# GMAC1 register map
Registers from a debugger description file.
Registers are 32-bit, access not given, no defined reset value unless marked. A register's access mark holds for its fields unless they carry their own. Addresses are absolute; registers are grouped by the start of their names; lines under a group give offsets from that group; [hi:lo] are bit positions; {n}, {i} and the like mark numbered series; 'fields as' and 'values as' point back to an identical list; <NAME> marks a mode.

## GMAC1
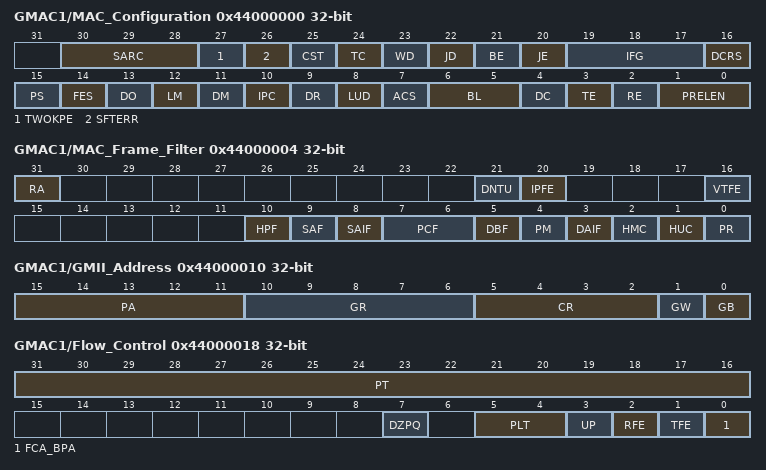
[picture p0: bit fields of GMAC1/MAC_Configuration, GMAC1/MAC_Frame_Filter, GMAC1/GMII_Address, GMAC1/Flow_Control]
0x44000000 GMAC1/MAC_Configuration
  [30:28] SARC, [27] TWOKPE, [26] SFTERR, [25] CST, [24] TC, [23] WD, [22] JD, [21] BE, [20] JE, [19:17] IFG, [16] DCRS, [15] PS, [14] FES, [13] DO, [12] LM, [11] DM, [10] IPC, [9] DR, [8] LUD, [7] ACS, [6:5] BL, [4] DC, [3] TE, [2] RE, [1:0] PRELEN
0x44000004 GMAC1/MAC_Frame_Filter
  [31] RA, [21] DNTU, [20] IPFE, [16] VTFE, [10] HPF, [9] SAF, [8] SAIF, [7:6] PCF, [5] DBF, [4] PM, [3] DAIF, [2] HMC, [1] HUC, [0] PR
0x44000010 GMAC1/GMII_Address
  [15:11] PA, [10:6] GR, [5:2] CR, [1] GW, [0] GB
0x44000014 GMAC1/GMII_Data
  [15:0] GD
0x44000018 GMAC1/Flow_Control
  [31:16] PT, [7] DZPQ, [5:4] PLT, [3] UP, [2] RFE, [1] TFE, [0] FCA_BPA
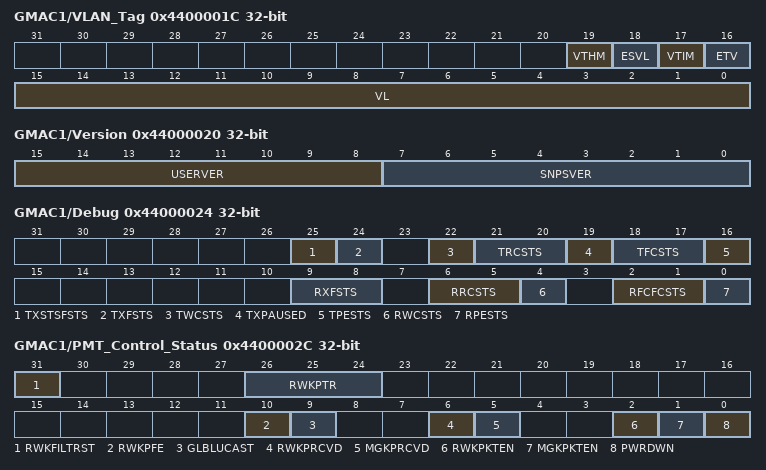
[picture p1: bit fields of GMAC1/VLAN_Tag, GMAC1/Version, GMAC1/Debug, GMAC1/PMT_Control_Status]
0x4400001C GMAC1/VLAN_Tag
  [19] VTHM, [18] ESVL, [17] VTIM, [16] ETV, [15:0] VL
0x44000020 GMAC1/Version ro
  [15:8] USERVER, [7:0] SNPSVER
0x44000024 GMAC1/Debug ro
  [25] TXSTSFSTS, [24] TXFSTS, [22] TWCSTS, [21:20] TRCSTS, [19] TXPAUSED, [18:17] TFCSTS, [16] TPESTS, [9:8] RXFSTS, [6:5] RRCSTS, [4] RWCSTS, [2:1] RFCFCSTS, [0] RPESTS
0x44000028 GMAC1/Remote_Wake_Up_Frame_Filter
  [31:0] WKUPFRMFTR
0x4400002C GMAC1/PMT_Control_Status
  [31] RWKFILTRST, [26:24] RWKPTR, [10] RWKPFE, [9] GLBLUCAST, [6] RWKPRCVD, [5] MGKPRCVD, [2] RWKPKTEN, [1] MGKPKTEN, [0] PWRDWN
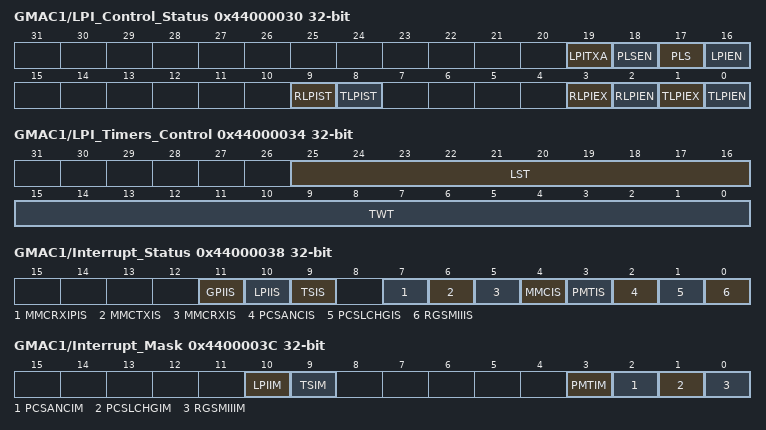
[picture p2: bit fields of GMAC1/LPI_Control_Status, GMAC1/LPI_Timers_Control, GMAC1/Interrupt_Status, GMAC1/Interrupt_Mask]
0x44000030 GMAC1/LPI_Control_Status
  [19] LPITXA, [18] PLSEN, [17] PLS, [16] LPIEN, [9] RLPIST, [8] TLPIST, [3] RLPIEX, [2] RLPIEN, [1] TLPIEX, [0] TLPIEN
0x44000034 GMAC1/LPI_Timers_Control
  [25:16] LST, [15:0] TWT
0x44000038 GMAC1/Interrupt_Status ro
  [11] GPIIS, [10] LPIIS, [9] TSIS, [7] MMCRXIPIS, [6] MMCTXIS, [5] MMCRXIS, [4] MMCIS, [3] PMTIS, [2] PCSANCIS, [1] PCSLCHGIS, [0] RGSMIIIS
0x4400003C GMAC1/Interrupt_Mask
  [10] LPIIM, [9] TSIM, [3] PMTIM, [2] PCSANCIM, [1] PCSLCHGIM, [0] RGSMIIIM
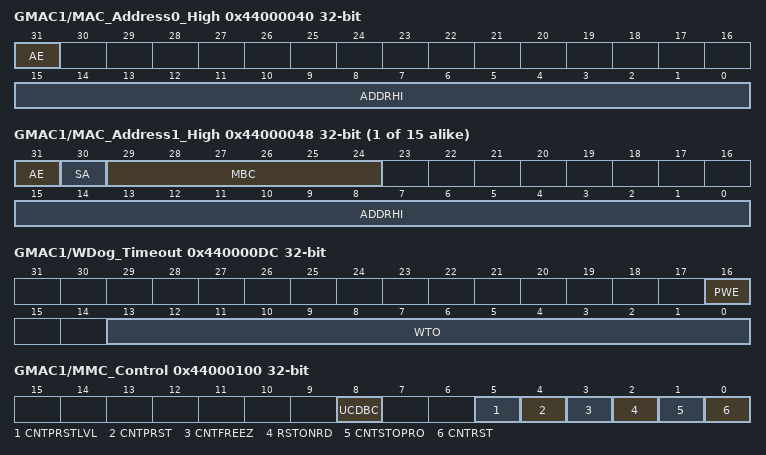
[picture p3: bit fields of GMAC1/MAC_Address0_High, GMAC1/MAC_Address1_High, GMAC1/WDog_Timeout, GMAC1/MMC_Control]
0x44000040 GMAC1/MAC_Address0_High
  [31] AE, [15:0] ADDRHI
{0x44000044+8i} GMAC1/MAC_Address{i}_Low (i=0..15)
  [31:0] ADDRLO
{0x44000040+8i} GMAC1/MAC_Address{i}_High (i=1..15)
  [31] AE, [30] SA, [29:24] MBC, [15:0] ADDRHI
0x440000DC GMAC1/WDog_Timeout
  [16] PWE, [13:0] WTO
0x44000100 GMAC1/MMC_Control
  [8] UCDBC, [5] CNTPRSTLVL, [4] CNTPRST, [3] CNTFREEZ, [2] RSTONRD, [1] CNTSTOPRO, [0] CNTRST
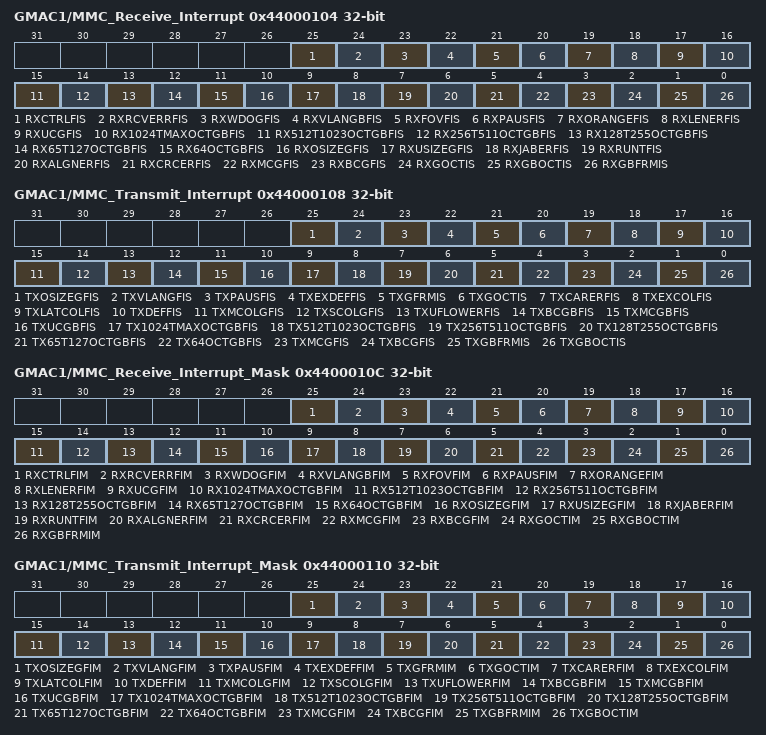
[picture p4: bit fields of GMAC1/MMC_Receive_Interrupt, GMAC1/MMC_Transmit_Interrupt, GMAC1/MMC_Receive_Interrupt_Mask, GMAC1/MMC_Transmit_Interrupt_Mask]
0x44000104 GMAC1/MMC_Receive_Interrupt ro
  [25] RXCTRLFIS, [24] RXRCVERRFIS, [23] RXWDOGFIS, [22] RXVLANGBFIS, [21] RXFOVFIS, [20] RXPAUSFIS, [19] RXORANGEFIS, [18] RXLENERFIS, [17] RXUCGFIS, [16] RX1024TMAXOCTGBFIS, [15] RX512T1023OCTGBFIS, [14] RX256T511OCTGBFIS, [13] RX128T255OCTGBFIS, [12] RX65T127OCTGBFIS, [11] RX64OCTGBFIS, [10] RXOSIZEGFIS, [9] RXUSIZEGFIS, [8] RXJABERFIS, [7] RXRUNTFIS, [6] RXALGNERFIS, [5] RXCRCERFIS, [4] RXMCGFIS, [3] RXBCGFIS, [2] RXGOCTIS, [1] RXGBOCTIS, [0] RXGBFRMIS
0x44000108 GMAC1/MMC_Transmit_Interrupt ro
  [25] TXOSIZEGFIS, [24] TXVLANGFIS, [23] TXPAUSFIS, [22] TXEXDEFFIS, [21] TXGFRMIS, [20] TXGOCTIS, [19] TXCARERFIS, [18] TXEXCOLFIS, [17] TXLATCOLFIS, [16] TXDEFFIS, [15] TXMCOLGFIS, [14] TXSCOLGFIS, [13] TXUFLOWERFIS, [12] TXBCGBFIS, [11] TXMCGBFIS, [10] TXUCGBFIS, [9] TX1024TMAXOCTGBFIS, [8] TX512T1023OCTGBFIS, [7] TX256T511OCTGBFIS, [6] TX128T255OCTGBFIS, [5] TX65T127OCTGBFIS, [4] TX64OCTGBFIS, [3] TXMCGFIS, [2] TXBCGFIS, [1] TXGBFRMIS, [0] TXGBOCTIS
0x4400010C GMAC1/MMC_Receive_Interrupt_Mask
  [25] RXCTRLFIM, [24] RXRCVERRFIM, [23] RXWDOGFIM, [22] RXVLANGBFIM, [21] RXFOVFIM, [20] RXPAUSFIM, [19] RXORANGEFIM, [18] RXLENERFIM, [17] RXUCGFIM, [16] RX1024TMAXOCTGBFIM, [15] RX512T1023OCTGBFIM, [14] RX256T511OCTGBFIM, [13] RX128T255OCTGBFIM, [12] RX65T127OCTGBFIM, [11] RX64OCTGBFIM, [10] RXOSIZEGFIM, [9] RXUSIZEGFIM, [8] RXJABERFIM, [7] RXRUNTFIM, [6] RXALGNERFIM, [5] RXCRCERFIM, [4] RXMCGFIM, [3] RXBCGFIM, [2] RXGOCTIM, [1] RXGBOCTIM, [0] RXGBFRMIM
0x44000110 GMAC1/MMC_Transmit_Interrupt_Mask
  [25] TXOSIZEGFIM, [24] TXVLANGFIM, [23] TXPAUSFIM, [22] TXEXDEFFIM, [21] TXGFRMIM, [20] TXGOCTIM, [19] TXCARERFIM, [18] TXEXCOLFIM, [17] TXLATCOLFIM, [16] TXDEFFIM, [15] TXMCOLGFIM, [14] TXSCOLGFIM, [13] TXUFLOWERFIM, [12] TXBCGBFIM, [11] TXMCGBFIM, [10] TXUCGBFIM, [9] TX1024TMAXOCTGBFIM, [8] TX512T1023OCTGBFIM, [7] TX256T511OCTGBFIM, [6] TX128T255OCTGBFIM, [5] TX65T127OCTGBFIM, [4] TX64OCTGBFIM, [3] TXMCGFIM, [2] TXBCGFIM, [1] TXGBFRMIM, [0] TXGBOCTIM
0x44000114 GMAC1/Tx_Octet_Count_Good_Bad ro
  [31:0] TXOCTGB
0x44000118 GMAC1/Tx_Frame_Count_Good_Bad ro
  [31:0] TXFRMGB
0x4400011C GMAC1/Tx_Broadcast_Frames_Good ro
  [31:0] TXBCASTG
0x44000120 GMAC1/Tx_Multicast_Frames_Good ro
  [31:0] TXMCASTG
0x44000124 GMAC1/Tx_64Octets_Frames_Good_Bad ro
  [31:0] TX64OCTGB
0x44000128 GMAC1/Tx_65To127Octets_Frames_Good_Bad ro
  [31:0] TX65_127OCTGB
0x4400012C GMAC1/Tx_128To255Octets_Frames_Good_Bad ro
  [31:0] TX128_255OCTGB
0x44000130 GMAC1/Tx_256To511Octets_Frames_Good_Bad ro
  [31:0] TX256_511OCTGB
0x44000134 GMAC1/Tx_512To1023Octets_Frames_Good_Bad ro
  [31:0] TX512_1023OCTGB
0x44000138 GMAC1/Tx_1024ToMaxOctets_Frames_Good_Bad ro
  [31:0] TX1024_MAXOCTGB
0x4400013C GMAC1/Tx_Unicast_Frames_Good_Bad ro
  [31:0] TXUCASTGB
0x44000140 GMAC1/Tx_Multicast_Frames_Good_Bad ro
  [31:0] TXMCASTGB
0x44000144 GMAC1/Tx_Broadcast_Frames_Good_Bad ro
  [31:0] TXBCASTGB
0x44000148 GMAC1/Tx_Underflow_Error_Frames ro
  [15:0] TXUNDRFLW
0x4400014C GMAC1/Tx_Single_Collision_Good_Frames ro
  [15:0] TXSNGLCOLG
0x44000150 GMAC1/Tx_Multiple_Collision_Good_Frames ro
  [15:0] TXMULTCOLG
0x44000154 GMAC1/Tx_Deferred_Frames ro
  [15:0] TXDEFRD
0x44000158 GMAC1/Tx_Late_Collision_Frames ro
  [15:0] TXLATECOL
0x4400015C GMAC1/Tx_Excessive_Collision_Frames ro
  [15:0] TXEXSCOL
0x44000160 GMAC1/Tx_Carrier_Error_Frames ro
  [15:0] TXCARR
0x44000164 GMAC1/Tx_Octet_Count_Good ro
  [31:0] TXOCTG
0x44000168 GMAC1/Tx_Frame_Count_Good ro
  [31:0] TXFRMG
0x4400016C GMAC1/Tx_Excessive_Deferral_Error ro
  [15:0] TXEXSDEF
0x44000170 GMAC1/Tx_Pause_Frames ro
  [15:0] TXPAUSE
0x44000174 GMAC1/Tx_VLAN_Frames_Good ro
  [31:0] TXVLANG
0x44000178 GMAC1/Tx_OSize_Frames_Good ro
  [15:0] TXOSIZG
0x44000180 GMAC1/Rx_Frames_Count_Good_Bad ro
  [31:0] RXFRMGB
0x44000184 GMAC1/Rx_Octet_Count_Good_Bad ro
  [31:0] RXOCTGB
0x44000188 GMAC1/Rx_Octet_Count_Good ro
  [31:0] RXOCTG
0x4400018C GMAC1/Rx_Broadcast_Frames_Good ro
  [31:0] RXBCASTG
0x44000190 GMAC1/Rx_Multicast_Frames_Good ro
  [31:0] RXMCASTG
0x44000194 GMAC1/Rx_CRC_Error_Frames ro
  [15:0] RXCRCERR
0x44000198 GMAC1/Rx_Alignment_Error_Frames ro
  [15:0] RXALGNERR
0x4400019C GMAC1/Rx_Runt_Error_Frames ro
  [15:0] RXRUNTERR
0x440001A0 GMAC1/Rx_Jabber_Error_Frames ro
  [15:0] RXJABERR
0x440001A4 GMAC1/Rx_Undersize_Frames_Good ro
  [15:0] RXUNDERSZG
0x440001A8 GMAC1/Rx_Oversize_Frames_Good ro
  [15:0] RXOVERSZG
0x440001AC GMAC1/Rx_64Octets_Frames_Good_Bad ro
  [31:0] RX64OCTGB
0x440001B0 GMAC1/Rx_65To127Octets_Frames_Good_Bad ro
  [31:0] RX65_127OCTGB
0x440001B4 GMAC1/Rx_128To255Octets_Frames_Good_Bad ro
  [31:0] RX128_255OCTGB
0x440001B8 GMAC1/Rx_256To511Octets_Frames_Good_Bad ro
  [31:0] RX256_511OCTGB
0x440001BC GMAC1/Rx_512To1023Octets_Frames_Good_Bad ro
  [31:0] RX512_1023OCTGB
0x440001C0 GMAC1/Rx_1024ToMaxOctets_Frames_Good_Bad ro
  [31:0] RX1024_MAXOCTGB
0x440001C4 GMAC1/Rx_Unicast_Frames_Good ro
  [31:0] RXUCASTG
0x440001C8 GMAC1/Rx_Length_Error_Frames ro
  [15:0] RXLENERR
0x440001CC GMAC1/Rx_Out_Of_Range_Type_Frames ro
  [15:0] RXOUTOFRNG
0x440001D0 GMAC1/Rx_Pause_Frames ro
  [15:0] RXPAUSEFRM
0x440001D4 GMAC1/Rx_FIFO_Overflow_Frames ro
  [15:0] RXFIFOOVFL
0x440001D8 GMAC1/Rx_VLAN_Frames_Good_Bad ro
  [31:0] RXVLANFRGB
0x440001DC GMAC1/Rx_Watchdog_Error_Frames ro
  [15:0] RXWDGERR
0x440001E0 GMAC1/Rx_Receive_Error_Frames ro
  [15:0] RXRCVERR
0x440001E4 GMAC1/Rx_Control_Frames_Good ro
  [31:0] RXCTRLG
{0x44000500+4i} GMAC1/Hash_Table_Reg{i} (i=0..5)
  [31:0] HT{32i+31}T{32i}
0x44000518 GMAC1/Hash_Table_Reg6
  [31:0] HT223T196
0x4400051C GMAC1/Hash_Table_Reg7
  [31:0] HT255T224
0x44000588 GMAC1/VLAN_Hash_Table_Reg
  [15:0] VLHT
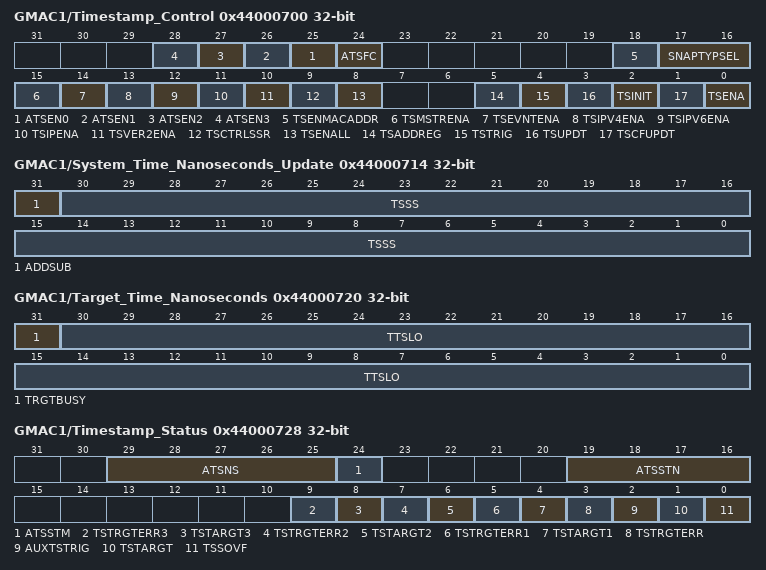
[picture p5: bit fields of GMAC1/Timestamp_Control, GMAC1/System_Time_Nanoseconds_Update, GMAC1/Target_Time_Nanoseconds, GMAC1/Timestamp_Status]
0x44000700 GMAC1/Timestamp_Control
  [n+25] ATSEN{n} (n=0..3), [24] ATSFC, [18] TSENMACADDR, [17:16] SNAPTYPSEL, [15] TSMSTRENA, [14] TSEVNTENA, [13] TSIPV4ENA, [12] TSIPV6ENA, [11] TSIPENA, [10] TSVER2ENA, [9] TSCTRLSSR, [8] TSENALL, [5] TSADDREG, [4] TSTRIG, [3] TSUPDT, [2] TSINIT, [1] TSCFUPDT, [0] TSENA
0x44000704 GMAC1/Sub_Second_Increment
  [7:0] SSINC
0x44000708 GMAC1/System_Time_Seconds ro
  [31:0] TSS
0x4400070C GMAC1/System_Time_Nanoseconds ro
  [30:0] TSSS
0x44000710 GMAC1/System_Time_Seconds_Update
  [31:0] TSS
0x44000714 GMAC1/System_Time_Nanoseconds_Update
  [31] ADDSUB, [30:0] TSSS
0x44000718 GMAC1/Timestamp_Addend
  [31:0] TSAR
0x4400071C GMAC1/Target_Time_Seconds
  [31:0] TSTR
0x44000720 GMAC1/Target_Time_Nanoseconds
  [31] TRGTBUSY, [30:0] TTSLO
0x44000728 GMAC1/Timestamp_Status ro
  [29:25] ATSNS, [24] ATSSTM, [19:16] ATSSTN, [9] TSTRGTERR3, [8] TSTARGT3, [7] TSTRGTERR2, [6] TSTARGT2, [5] TSTRGTERR1, [4] TSTARGT1, [3] TSTRGTERR, [2] AUXTSTRIG, [1] TSTARGT, [0] TSSOVF
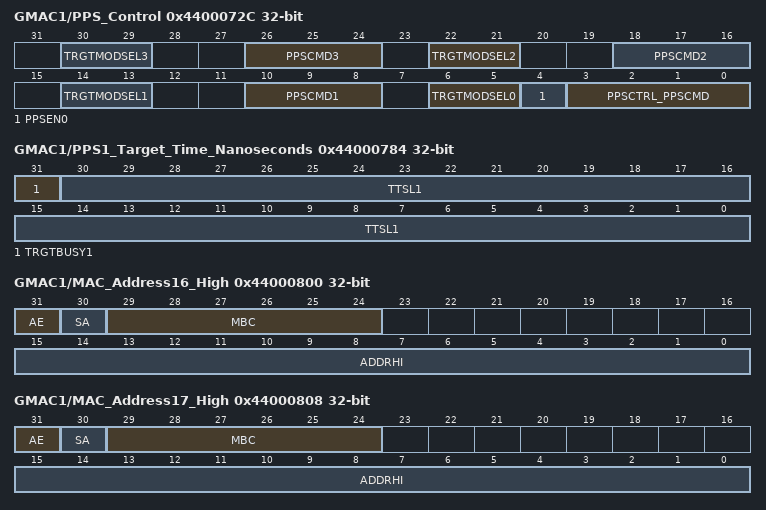
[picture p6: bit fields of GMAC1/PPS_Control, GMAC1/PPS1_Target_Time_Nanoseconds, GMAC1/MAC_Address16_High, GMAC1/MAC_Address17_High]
0x4400072C GMAC1/PPS_Control
  [8n+6:8n+5] TRGTMODSEL{n} (n=0..3), [26:24] PPSCMD3, [18:16] PPSCMD2, [10:8] PPSCMD1, [4] PPSEN0, [3:0] PPSCTRL_PPSCMD
0x44000730 GMAC1/Auxiliary_Timestamp_Nanoseconds ro
  [30:0] AUXTSLO
0x44000734 GMAC1/Auxiliary_Timestamp_Seconds ro
  [31:0] AUXTSHI
0x44000760 GMAC1/PPS0_Interval
  [31:0] PPSINT
0x44000764 GMAC1/PPS0_Width
  [31:0] PPSWIDTH
0x44000780 GMAC1/PPS1_Target_Time_Seconds
  [31:0] TSTRH1
0x44000784 GMAC1/PPS1_Target_Time_Nanoseconds
  [31] TRGTBUSY1, [30:0] TTSL1
0x44000788 GMAC1/PPS1_Interval
  [31:0] PPSINT
0x4400078C GMAC1/PPS1_Width
  [31:0] PPSWIDTH
0x44000800 GMAC1/MAC_Address16_High
  [31] AE, [30] SA, [29:24] MBC, [15:0] ADDRHI
0x44000804 GMAC1/MAC_Address16_Low
  [31:0] ADDRLO
0x44000808 GMAC1/MAC_Address17_High
  [31] AE, [30] SA, [29:24] MBC, [15:0] ADDRHI
0x4400080C GMAC1/MAC_Address17_Low
  [31:0] ADDRLO
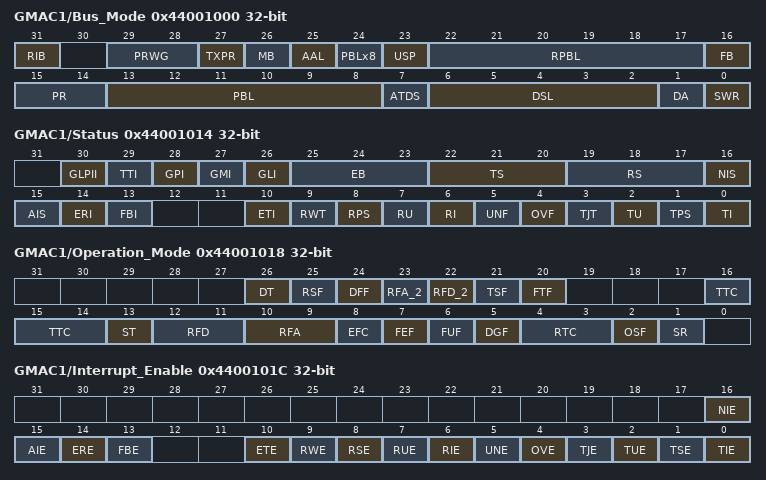
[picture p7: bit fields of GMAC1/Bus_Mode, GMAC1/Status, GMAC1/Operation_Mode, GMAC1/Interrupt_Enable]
0x44001000 GMAC1/Bus_Mode
  [31] RIB, [29:28] PRWG, [27] TXPR, [26] MB, [25] AAL, [24] PBLx8, [23] USP, [22:17] RPBL, [16] FB, [15:14] PR, [13:8] PBL, [7] ATDS, [6:2] DSL, [1] DA, [0] SWR
0x44001004 GMAC1/Transmit_Poll_Demand
  [31:0] TPD
0x44001008 GMAC1/Receive_Poll_Demand
  [31:0] RPD
0x4400100C GMAC1/Receive_Descriptor_List_Address
  [31:2] RDESLA_32bit
0x44001010 GMAC1/Transmit_Descriptor_List_Address
  [31:2] TDESLA_32bit
0x44001014 GMAC1/Status
  [30] GLPII, [29] TTI, [28] GPI, [27] GMI, [26] GLI, [25:23] EB, [22:20] TS, [19:17] RS, [16] NIS, [15] AIS, [14] ERI, [13] FBI, [10] ETI, [9] RWT, [8] RPS, [7] RU, [6] RI, [5] UNF, [4] OVF, [3] TJT, [2] TU, [1] TPS, [0] TI
0x44001018 GMAC1/Operation_Mode
  [26] DT, [25] RSF, [24] DFF, [23] RFA_2, [22] RFD_2, [21] TSF, [20] FTF, [16:14] TTC, [13] ST, [12:11] RFD, [10:9] RFA, [8] EFC, [7] FEF, [6] FUF, [5] DGF, [4:3] RTC, [2] OSF, [1] SR
0x4400101C GMAC1/Interrupt_Enable
  [16] NIE, [15] AIE, [14] ERE, [13] FBE, [10] ETE, [9] RWE, [8] RSE, [7] RUE, [6] RIE, [5] UNE, [4] OVE, [3] TJE, [2] TUE, [1] TSE, [0] TIE
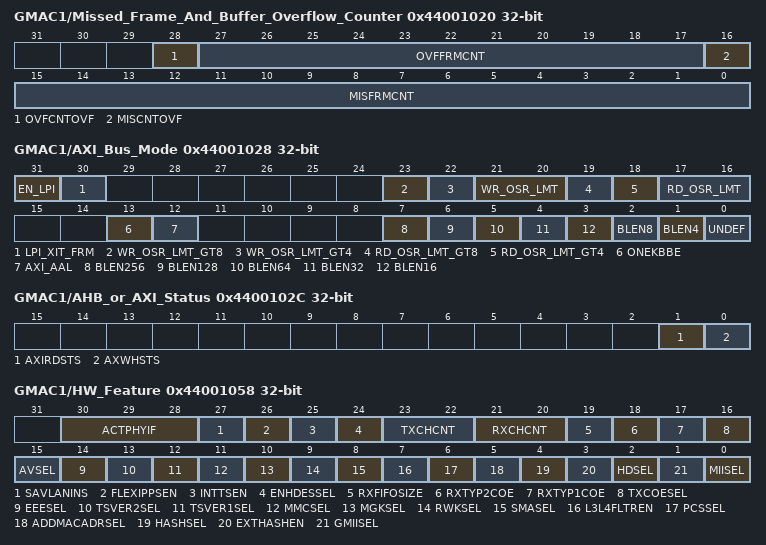
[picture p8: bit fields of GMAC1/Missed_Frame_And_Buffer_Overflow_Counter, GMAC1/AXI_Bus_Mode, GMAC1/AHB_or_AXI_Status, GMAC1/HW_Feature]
0x44001020 GMAC1/Missed_Frame_And_Buffer_Overflow_Counter ro
  [28] OVFCNTOVF, [27:17] OVFFRMCNT, [16] MISCNTOVF, [15:0] MISFRMCNT
0x44001024 GMAC1/Receive_Interrupt_Watchdog_Timer
  [7:0] RIWT
0x44001028 GMAC1/AXI_Bus_Mode
  [31] EN_LPI, [30] LPI_XIT_FRM, [23] WR_OSR_LMT_GT8, [22] WR_OSR_LMT_GT4, [21:20] WR_OSR_LMT, [19] RD_OSR_LMT_GT8, [18] RD_OSR_LMT_GT4, [17:16] RD_OSR_LMT, [13] ONEKBBE, [12] AXI_AAL, [7] BLEN256, [6] BLEN128, [5] BLEN64, [4] BLEN32, [3] BLEN16, [2] BLEN8, [1] BLEN4, [0] UNDEF
0x4400102C GMAC1/AHB_or_AXI_Status ro
  [1] AXIRDSTS, [0] AXWHSTS
0x44001048 GMAC1/Current_Host_Transmit_Descriptor ro
  [31:0] CURTDESAPTR
0x4400104C GMAC1/Current_Host_Receive_Descriptor ro
  [31:0] CURRDESAPTR
0x44001050 GMAC1/Current_Host_Transmit_Buffer_Address ro
  [31:0] CURTBUFAPTR
0x44001054 GMAC1/Current_Host_Receive_Buffer_Address ro
  [31:0] CURRBUFAPTR
0x44001058 GMAC1/HW_Feature ro
  [30:28] ACTPHYIF, [27] SAVLANINS, [26] FLEXIPPSEN, [25] INTTSEN, [24] ENHDESSEL, [23:22] TXCHCNT, [21:20] RXCHCNT, [19] RXFIFOSIZE, [18] RXTYP2COE, [17] RXTYP1COE, [16] TXCOESEL, [15] AVSEL, [14] EEESEL, [13] TSVER2SEL, [12] TSVER1SEL, [11] MMCSEL, [10] MGKSEL, [9] RWKSEL, [8] SMASEL, [7] L3L4FLTREN, [6] PCSSEL, [5] ADDMACADRSEL, [4] HASHSEL, [3] EXTHASHEN, [2] HDSEL, [1] GMIISEL, [0] MIISEL
